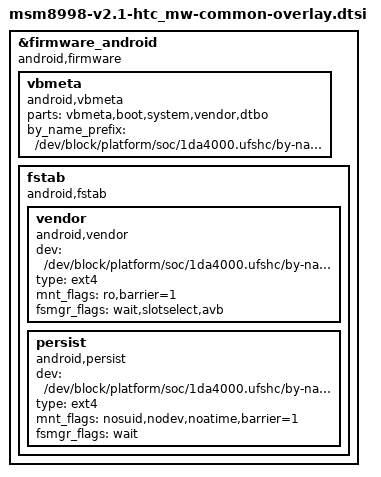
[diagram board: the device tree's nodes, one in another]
/* Copyright (c) 2016, The Linux Foundation. All rights reserved.
 *
 * This program is free software; you can redistribute it and/or modify
 * it under the terms of the GNU General Public License version 2 and
 * only version 2 as published by the Free Software Foundation.
 *
 * This program is distributed in the hope that it will be useful,
 * but WITHOUT ANY WARRANTY; without even the implied warranty of
 * MERCHANTABILITY or FITNESS FOR A PARTICULAR PURPOSE.  See the
 * GNU General Public License for more details.
 */

#include <dt-bindings/clock/msm-clocks-8998.h>

#include "base-msm8998-mtp.dtsi"
#include "msm8998-htc_muskie.dtsi"
#include "msm8998-htc-nfc.dtsi"
#include "msm8998-htc-usb-xa.dtsi"
#include "msm8998-htc-easel.dtsi"
#include "msm8998-camera-sensor-muskie-xa.dtsi"
#include "msm8998-htc-fingerprint-muskie-xa.dtsi"
#include "msm8998-htc-haptics-xa.dtsi"
#include "msm8998-htc-edge.dtsi"

&firmware_android {
	compatible = "android,firmware";
	vbmeta {
		compatible = "android,vbmeta";
		parts = "vbmeta,boot,system,vendor,dtbo";
		by_name_prefix = "/dev/block/platform/soc/1da4000.ufshc/by-name";
	};
	fstab {
		compatible = "android,fstab";
		vendor {
			compatible = "android,vendor";
			dev = "/dev/block/platform/soc/1da4000.ufshc/by-name/vendor";
			type = "ext4";
			mnt_flags = "ro,barrier=1";
			fsmgr_flags = "wait,slotselect,avb";
		};
		persist {
			compatible = "android,persist";
			dev = "/dev/block/platform/soc/1da4000.ufshc/by-name/persist";
			type = "ext4";
			mnt_flags = "nosuid,nodev,noatime,barrier=1";
			fsmgr_flags = "wait";
		};
	};
};
